# NAVSS0_UDMASS_INTA_0_UDMASS_INTA0_CFG register map
Vendor: Texas Instruments
Peripheral module from a debugger description file (folder J721S2).
Registers are 64-bit, read-only, reset 0x66961101 unless marked. A register's access mark holds for its fields unless they carry their own. Offsets are as the file gives them; lines under a group give offsets from that group; [hi:lo] are bit positions; {n}, {i} and the like mark numbered series; 'fields as' and 'values as' point back to an identical list; <NAME> marks a mode.

## NAVSS0_UDMASS_INTA_0_UDMASS_INTA0_CFG
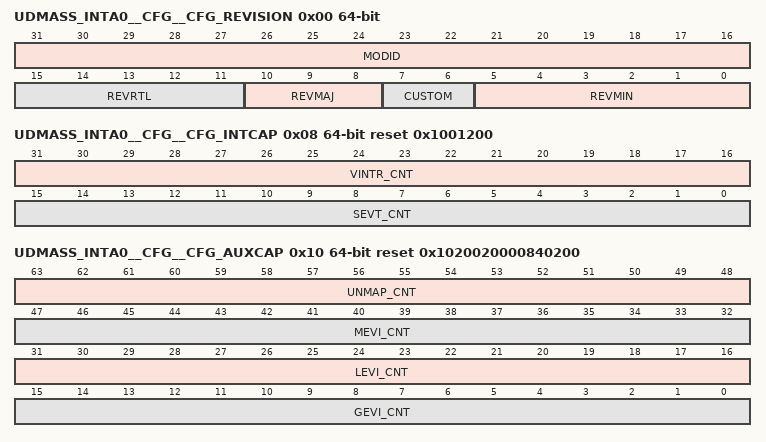
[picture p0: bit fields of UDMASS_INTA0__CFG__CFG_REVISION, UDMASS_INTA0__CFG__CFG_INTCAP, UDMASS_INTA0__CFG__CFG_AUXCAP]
0x00 UDMASS_INTA0__CFG__CFG_REVISION — The Revision Register contains the major and minor revisions for the module.
  [31:16] MODID — Module ID field
  [15:11] REVRTL — RTL revision. Will vary depending on release.
  [10:8] REVMAJ — Major revision
  [7:6] CUSTOM
  [5:0] REVMIN — Minor revision
0x08 UDMASS_INTA0__CFG__CFG_INTCAP reset 0x1001200 — The IntCap Register contains information on virtual interrupts.
  [31:16] VINTR_CNT — Virtual interrupt register/pin count
  [15:0] SEVT_CNT — Number of 'event to virt int' mapping registers
0x10 UDMASS_INTA0__CFG__CFG_AUXCAP reset 0x1020020000840200 — The AuxCap Register contains information on additional capabilities.
  [63:48] UNMAP_CNT — Number of multicast event registers. Not all registers in the range are necessarily valid.
  [47:32] MEVI_CNT — Number of multicast event registers
  [31:16] LEVI_CNT — Local input events for local to global translation
  [15:0] GEVI_CNT — Number of event counting registers
